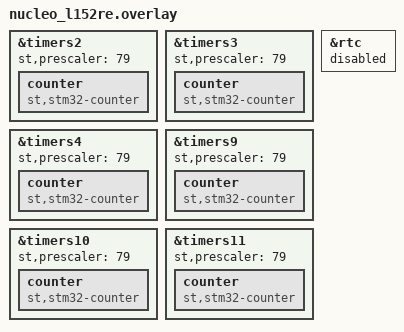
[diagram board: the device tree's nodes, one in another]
&timers2 {
	st,prescaler = <79>;
	counter {
		compatible = "st,stm32-counter";
		status = "okay";
	};
};

&timers3 {
	st,prescaler = <79>;
	counter {
		compatible = "st,stm32-counter";
		status = "okay";
	};
};

&timers4 {
	st,prescaler = <79>;
	status = "okay";
	counter {
		compatible = "st,stm32-counter";
		status = "okay";
	};
};

&timers9 {
	st,prescaler = <79>;
	status = "okay";
	counter {
		compatible = "st,stm32-counter";
		status = "okay";
	};
};

&timers10 {
	st,prescaler = <79>;
	status = "okay";
	counter {
		compatible = "st,stm32-counter";
		status = "okay";
	};
};

&timers11 {
	st,prescaler = <79>;
	status = "okay";
	counter {
		compatible = "st,stm32-counter";
		status = "okay";
	};
};

&rtc {
	status = "disabled";
};
